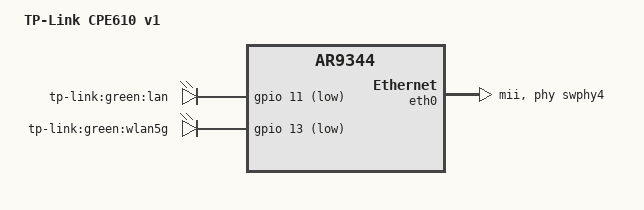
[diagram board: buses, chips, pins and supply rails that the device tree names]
// SPDX-License-Identifier: GPL-2.0-or-later OR MIT
/dts-v1/;

#include "ar9344_tplink_cpexxx.dtsi"

/ {
	model = "TP-Link CPE610 v1";
	compatible = "tplink,cpe610-v1", "qca,ar9344";

	aliases {
		led-boot = &system;
		led-failsafe = &system;
		led-upgrade = &system;
	};

	leds {
		compatible = "gpio-leds";

		system: lan {
			label = "tp-link:green:lan";
			gpios = <&gpio 11 GPIO_ACTIVE_LOW>;
		};

		wlan5g {
			label = "tp-link:green:wlan5g";
			gpios = <&gpio 13 GPIO_ACTIVE_LOW>;
			linux,default-trigger = "phy0tpt";
		};
	};
};

&eth0 {
	status = "okay";

	mtd-mac-address = <&info 0x08>;

	phy-mode = "mii";
	phy-handle = <&swphy4>;
};

&eth1 {
	status = "okay";
	compatible = "syscon", "simple-mfd";
};
